# STM32F107 register map
File version: 1.2
CPU: CM3 r1p1, little endian, no MPU, no FPU, 4 interrupt priority bits
Registers are 32-bit, read-write, reset 0x0 unless marked. A register's access mark holds for its fields unless they carry their own. Offsets are from the block's base; [hi:lo] are bit positions; {n}, {i} and the like mark numbered series; 'fields as' and 'values as' point back to an identical list.

## USB_OTG_HOST — USB on the go full speed
Base 0x50000400
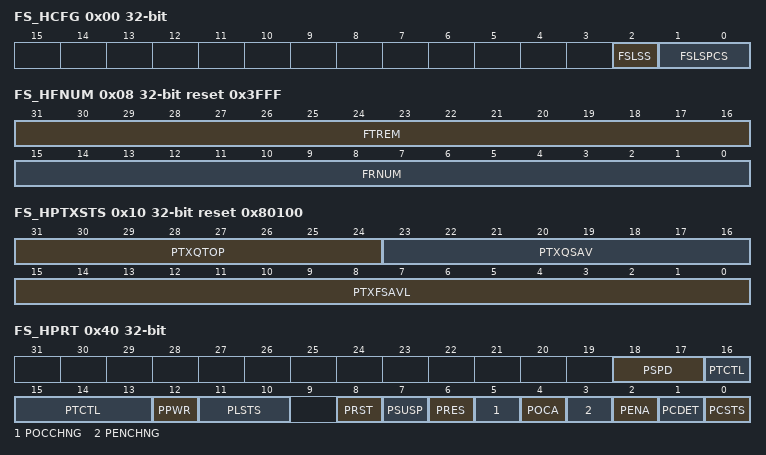
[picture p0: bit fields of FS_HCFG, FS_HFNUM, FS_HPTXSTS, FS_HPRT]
0x00 FS_HCFG access per field — OTG_FS host configuration register (OTG_FS_HCFG)
  [2] FSLSS ro — FS- and LS-only support
  [1:0] FSLSPCS rw — FS/LS PHY clock select
0x04 HFIR reset 0xEA60 — OTG_FS Host frame interval register
  [15:0] FRIVL — Frame interval
0x08 FS_HFNUM ro reset 0x3FFF — OTG_FS host frame number/frame time remaining register (OTG_FS_HFNUM)
  [31:16] FTREM — Frame time remaining
  [15:0] FRNUM — Frame number
0x10 FS_HPTXSTS access per field reset 0x80100 — OTG_FS_Host periodic transmit FIFO/queue status register (OTG_FS_HPTXSTS)
  [31:24] PTXQTOP ro — Top of the periodic transmit request queue
  [23:16] PTXQSAV ro — Periodic transmit request queue space available
  [15:0] PTXFSAVL rw — Periodic transmit data FIFO space available
0x14 HAINT ro — OTG_FS Host all channels interrupt register
  [15:0] HAINT — Channel interrupts
0x18 HAINTMSK — OTG_FS host all channels interrupt mask register
  [15:0] HAINTM — Channel interrupt mask
0x40 FS_HPRT access per field — OTG_FS host port control and status register (OTG_FS_HPRT)
  [18:17] PSPD ro — Port speed
  [16:13] PTCTL rw — Port test control
  [12] PPWR rw — Port power
  [11:10] PLSTS ro — Port line status
  [8] PRST rw — Port reset
  [7] PSUSP rw — Port suspend
  [6] PRES rw — Port resume
  [5] POCCHNG rw — Port overcurrent change
  [4] POCA ro — Port overcurrent active
  [3] PENCHNG rw — Port enable/disable change
  [2] PENA rw — Port enable
  [1] PCDET rw — Port connect detected
  [0] PCSTS ro — Port connect status
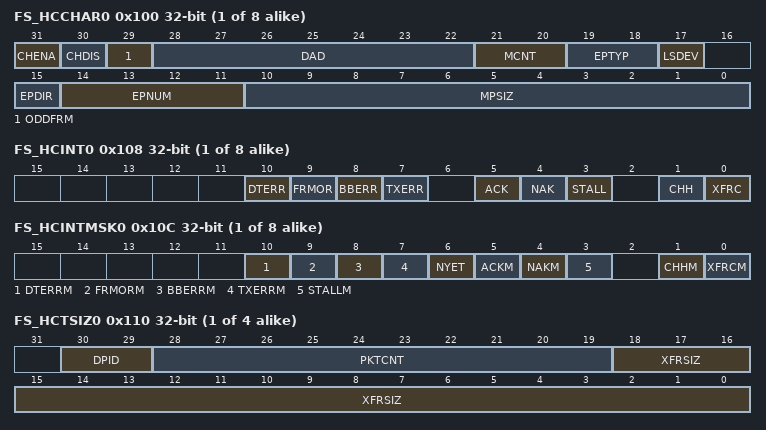
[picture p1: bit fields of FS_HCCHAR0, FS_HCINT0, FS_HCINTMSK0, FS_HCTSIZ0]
{0x100+0x20*i} FS_HCCHAR{i} (i=0..7) — OTG_FS host channel-{i} characteristics register (OTG_FS_HCCHAR{i})
  [31] CHENA — Channel enable
  [30] CHDIS — Channel disable
  [29] ODDFRM — Odd frame
  [28:22] DAD — Device address
  [21:20] MCNT — Multicount
  [19:18] EPTYP — Endpoint type
  [17] LSDEV — Low-speed device
  [15] EPDIR — Endpoint direction
  [14:11] EPNUM — Endpoint number
  [10:0] MPSIZ — Maximum packet size
{0x108+0x20*i} FS_HCINT{i} (i=0..7) — OTG_FS host channel-{i} interrupt register (OTG_FS_HCINT{i})
  [10] DTERR — Data toggle error
  [9] FRMOR — Frame overrun
  [8] BBERR — Babble error
  [7] TXERR — Transaction error
  [5] ACK — ACK response received/transmitted interrupt
  [4] NAK — NAK response received interrupt
  [3] STALL — STALL response received interrupt
  [1] CHH — Channel halted
  [0] XFRC — Transfer completed
{0x10C+0x20*i} FS_HCINTMSK{i} (i=0..7) — OTG_FS host channel-{i} mask register (OTG_FS_HCINTMSK{i})
  [10] DTERRM — Data toggle error mask
  [9] FRMORM — Frame overrun mask
  [8] BBERRM — Babble error mask
  [7] TXERRM — Transaction error mask
  [6] NYET — response received interrupt mask
  [5] ACKM — ACK response received/transmitted interrupt mask
  [4] NAKM — NAK response received interrupt mask
  [3] STALLM — STALL response received interrupt mask
  [1] CHHM — Channel halted mask
  [0] XFRCM — Transfer completed mask
{0x110+0x20*i} FS_HCTSIZ{i} (i=0..3) — OTG_FS host channel-{i} transfer size register
  [30:29] DPID — Data PID
  [28:19] PKTCNT — Packet count
  [18:0] XFRSIZ — Transfer size
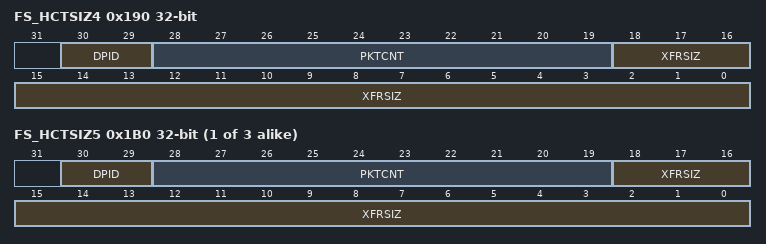
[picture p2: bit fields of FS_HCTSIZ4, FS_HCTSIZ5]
0x190 FS_HCTSIZ4 — OTG_FS host channel-x transfer size register
  fields as FS_HCTSIZ0
{0x110+0x20*i} FS_HCTSIZ{i} (i=5..7) — OTG_FS host channel-{i} transfer size register
  fields as FS_HCTSIZ0

## USB_OTG_PWRCLK — USB on the go full speed
Base 0x50000E00
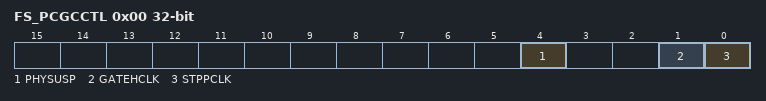
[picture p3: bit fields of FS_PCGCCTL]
0x00 FS_PCGCCTL — OTG_FS power and clock gating control register (OTG_FS_PCGCCTL)
  [4] PHYSUSP — PHY Suspended
  [1] GATEHCLK
  [0] STPPCLK — Stop PHY clock

## DAC — Digital to analog converter
Base 0x40007400
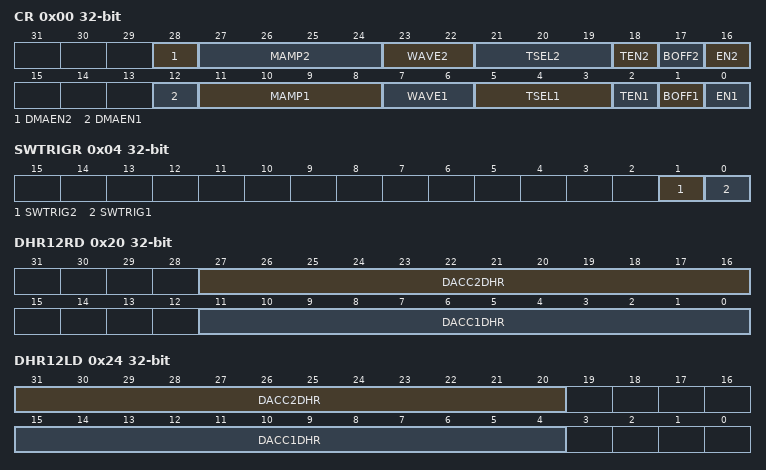
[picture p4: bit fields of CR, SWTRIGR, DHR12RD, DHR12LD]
0x00 CR — Control register (DAC_CR)
  [28] DMAEN2 — DAC channel2 DMA enable
  [27:24] MAMP2 — DAC channel2 mask/amplitude selector
  [23:22] WAVE2 — DAC channel2 noise/triangle wave generation enable
  [21:19] TSEL2 — DAC channel2 trigger selection
  [18] TEN2 — DAC channel2 trigger enable
  [17] BOFF2 — DAC channel2 output buffer disable
  [16] EN2 — DAC channel2 enable
  [12] DMAEN1 — DAC channel1 DMA enable
  [11:8] MAMP1 — DAC channel1 mask/amplitude selector
  [7:6] WAVE1 — DAC channel1 noise/triangle wave generation enable
  [5:3] TSEL1 — DAC channel1 trigger selection
  [2] TEN1 — DAC channel1 trigger enable
  [1] BOFF1 — DAC channel1 output buffer disable
  [0] EN1 — DAC channel1 enable
0x04 SWTRIGR wo — DAC software trigger register (DAC_SWTRIGR)
  [1] SWTRIG2 — DAC channel2 software trigger
  [0] SWTRIG1 — DAC channel1 software trigger
0x08 DHR12R1 — DAC channel1 12-bit right-aligned data holding register(DAC_DHR12R1)
  [11:0] DACC1DHR — DAC channel1 12-bit right-aligned data
0x0C DHR12L1 — DAC channel1 12-bit left aligned data holding register (DAC_DHR12L1)
  [15:4] DACC1DHR — DAC channel1 12-bit left-aligned data
0x10 DHR8R1 — DAC channel1 8-bit right aligned data holding register (DAC_DHR8R1)
  [7:0] DACC1DHR — DAC channel1 8-bit right-aligned data
0x14 DHR12R2 — DAC channel2 12-bit right aligned data holding register (DAC_DHR12R2)
  [11:0] DACC2DHR — DAC channel2 12-bit right-aligned data
0x18 DHR12L2 — DAC channel2 12-bit left aligned data holding register (DAC_DHR12L2)
  [15:4] DACC2DHR — DAC channel2 12-bit left-aligned data
0x1C DHR8R2 — DAC channel2 8-bit right-aligned data holding register (DAC_DHR8R2)
  [7:0] DACC2DHR — DAC channel2 8-bit right-aligned data
0x20 DHR12RD — Dual DAC 12-bit right-aligned data holding register (DAC_DHR12RD), Bits 31:28 Reserved, Bits 15:12 Reserved
  [27:16] DACC2DHR — DAC channel2 12-bit right-aligned data
  [11:0] DACC1DHR — DAC channel1 12-bit right-aligned data
0x24 DHR12LD — DUAL DAC 12-bit left aligned data holding register (DAC_DHR12LD), Bits 19:16 Reserved, Bits 3:0 Reserved
  [31:20] DACC2DHR — DAC channel2 12-bit right-aligned data
  [15:4] DACC1DHR — DAC channel1 12-bit left-aligned data
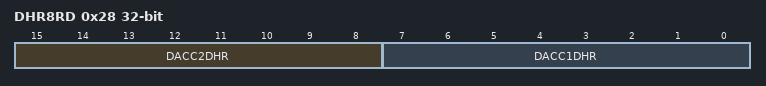
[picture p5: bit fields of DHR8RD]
0x28 DHR8RD — DUAL DAC 8-bit right aligned data holding register (DAC_DHR8RD), Bits 31:16 Reserved
  [15:8] DACC2DHR — DAC channel2 8-bit right-aligned data
  [7:0] DACC1DHR — DAC channel1 8-bit right-aligned data
0x2C DOR1 ro — DAC channel1 data output register (DAC_DOR1)
  [11:0] DACC1DOR — DAC channel1 data output
0x30 DOR2 ro — DAC channel2 data output register (DAC_DOR2)
  [11:0] DACC2DOR — DAC channel2 data output
